# shamd5dma register map
Vendor: Texas Instruments
Peripheral module from a debugger description file (folder MSP432E4).
Registers are 32-bit, read-only, no defined reset value unless marked. A register's access mark holds for its fields unless they carry their own. Offsets are as the file gives them; lines under a group give offsets from that group; [hi:lo] are bit positions; {n}, {i} and the like mark numbered series; 'fields as' and 'values as' point back to an identical list; <NAME> marks a mode.

## SHAMD5_DMA — SHA/MD5 DMA register offsets
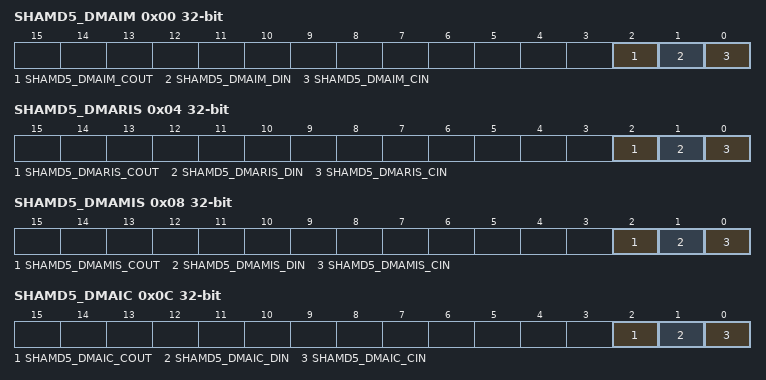
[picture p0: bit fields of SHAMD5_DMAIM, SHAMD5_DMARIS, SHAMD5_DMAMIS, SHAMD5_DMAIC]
0x00 SHAMD5_DMAIM rw — SHA DMA Interrupt Mask
  [2] SHAMD5_DMAIM_COUT — Context Out DMA Done Interrupt Mask
  [1] SHAMD5_DMAIM_DIN — Data In DMA Done Interrupt Mask
  [0] SHAMD5_DMAIM_CIN — Context In DMA Done Interrupt Mask
0x04 SHAMD5_DMARIS — SHA DMA Raw Interrupt Status
  [2] SHAMD5_DMARIS_COUT — Context Out DMA Done Raw Interrupt Status
  [1] SHAMD5_DMARIS_DIN — Data In DMA Done Raw Interrupt Status
  [0] SHAMD5_DMARIS_CIN — Context In DMA Done Raw Interrupt Status
0x08 SHAMD5_DMAMIS — SHA DMA Masked Interrupt Status
  [2] SHAMD5_DMAMIS_COUT — Context Out DMA Done Masked Interrupt Status
  [1] SHAMD5_DMAMIS_DIN — Data In DMA Done Masked Interrupt Status
  [0] SHAMD5_DMAMIS_CIN — Context In DMA Done Raw Interrupt Status
0x0C SHAMD5_DMAIC wo — SHA DMA Interrupt Clear
  [2] SHAMD5_DMAIC_COUT — Context Out DMA Done Masked Interrupt Status
  [1] SHAMD5_DMAIC_DIN — Data In DMA Done Interrupt Clear
  [0] SHAMD5_DMAIC_CIN — Context In DMA Done Raw Interrupt Status
